VERSION ""

NS_ :

BS_:

BU_:

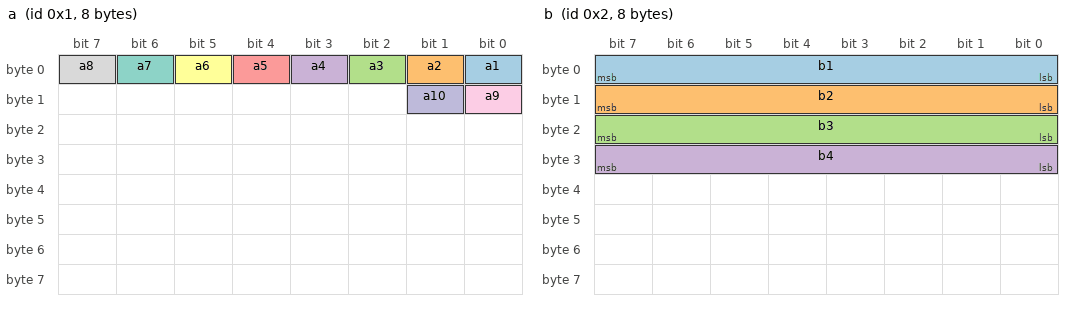
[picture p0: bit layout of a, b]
BO_ 1 a: 8 Vector__XXX
 SG_ a1 : 0|1@1+ (1,-127) [0|0] "" Vector__XXX
 SG_ a2 : 1|1@1+ (1,-127) [0|0] "" Vector__XXX
 SG_ a3 : 2|1@1+ (1,-127) [0|0] "" Vector__XXX
 SG_ a4 : 3|1@1+ (1,-127) [0|0] "" Vector__XXX
 SG_ a5 : 4|1@1+ (1,-127) [0|0] "" Vector__XXX
 SG_ a6 : 5|1@1+ (1,-127) [0|0] "" Vector__XXX
 SG_ a7 : 6|1@1+ (1,-127) [0|0] "" Vector__XXX
 SG_ a8 : 7|1@1+ (1,-127) [0|0] "" Vector__XXX
 SG_ a9 : 8|1@1+ (1,-127) [0|0] "" Vector__XXX
 SG_ a10 : 9|1@1+ (1,-127) [0|0] "" Vector__XXX

BO_ 2 b: 8 Vector__XXX
 SG_ b1 : 0|8@1+ (1,0) [0|0] "" Vector__XXX
 SG_ b2 : 8|8@1+ (1,0) [0|0] "" Vector__XXX
 SG_ b3 : 16|8@1+ (1,0) [0|0] "" Vector__XXX
 SG_ b4 : 24|8@1+ (1,0) [0|0] "" Vector__XXX

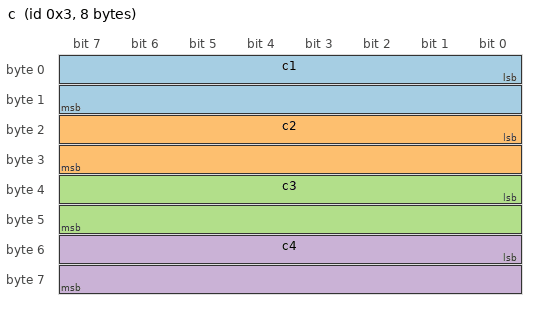
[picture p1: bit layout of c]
BO_ 3 c: 8 Vector__XXX
 SG_ c1 : 0|16@1- (1,0) [0|0] "" Vector__XXX
 SG_ c2 : 16|16@1- (1,0) [0|0] "" Vector__XXX
 SG_ c3 : 32|16@1- (1,0) [0|0] "" Vector__XXX
 SG_ c4 : 48|16@1- (1,0) [0|0] "" Vector__XXX
